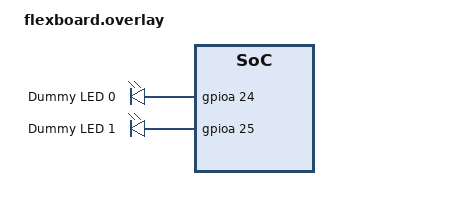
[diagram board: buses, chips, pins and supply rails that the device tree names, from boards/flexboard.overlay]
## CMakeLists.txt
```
# SPDX-License-Identifier: Apache-2.0

cmake_minimum_required(VERSION 3.20.0)

# Add custom board root dir
list(APPEND BOARD_ROOT ${CMAKE_CURRENT_SOURCE_DIR}/../../)

find_package(Zephyr REQUIRED HINTS $ENV{ZEPHYR_BASE})
project(hello_world)

target_sources(app PRIVATE src/main.c src/loop.S)
```

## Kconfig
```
# Copyright 2022 Daniel DeGrasse
# SPDX-License-Identifier: Apache-2.0

source "Kconfig.zephyr"

config ENABLE_DEBUG_LOOP
    bool "Enable debug loop at boot"
    default y
    select PLATFORM_SPECIFIC_INIT
    help
      Hold device in loop at platform boot. Can be disabled once
      device is confirmed to be stable.
```

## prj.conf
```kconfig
CONFIG_SHELL=y
CONFIG_I2C=y
CONFIG_GPIO=y
CONFIG_I2C_SHELL=y
CONFIG_GPIO_SHELL=y
```

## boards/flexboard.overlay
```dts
/*
 * Enable GPIO port A, and add two dummy LED aliases. The flexboard has no
 * LEDs present, so this overlay simply allows the test to build and run.
 */

/ {
	aliases {
		led0 = &dummy_led0;
		led1 = &dummy_led1;
	};

	leds {
		compatible = "gpio-leds";
		dummy_led0: led_0 {
			gpios = <&gpioa 24 0>;
			label = "Dummy LED 0";
		};
		dummy_led1: led_1 {
			gpios = <&gpioa 25 0>;
			label = "Dummy LED 1";
		};
	};
};





&gpioa {
	status = "okay";
};
```

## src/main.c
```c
/*
 * Copyright (c) 2012-2014 Wind River Systems, Inc.
 *
 * SPDX-License-Identifier: Apache-2.0
 */

#include <zephyr/kernel.h>
#include <zephyr/drivers/gpio.h>

/* 1000 msec = 1 sec */
#define SLEEP_TIME_MS   1000

#define LED0_NODE DT_ALIAS(led0)
#define LED1_NODE DT_ALIAS(led1)

static const struct gpio_dt_spec led0 = GPIO_DT_SPEC_GET(LED0_NODE, gpios);
static const struct gpio_dt_spec led1 = GPIO_DT_SPEC_GET(LED1_NODE, gpios);

void main(void)
{
	int ret;

	if (!device_is_ready(led0.port) ||
		!device_is_ready(led1.port)) {
		return;
	}

	ret = gpio_pin_configure_dt(&led0, GPIO_OUTPUT_ACTIVE);
	if (ret < 0) {
		return;
	}

	ret = gpio_pin_configure_dt(&led1, GPIO_OUTPUT_INACTIVE);
	if (ret < 0) {
		return;
	}

	printk("Hello World! %s\n", CONFIG_BOARD);
	while (1) {
		ret = gpio_pin_toggle_dt(&led0);
		if (ret < 0) {
			return;
		}
		ret = gpio_pin_toggle_dt(&led1);
		if (ret < 0) {
			return;
		}
		k_msleep(SLEEP_TIME_MS);
	}
}
```
